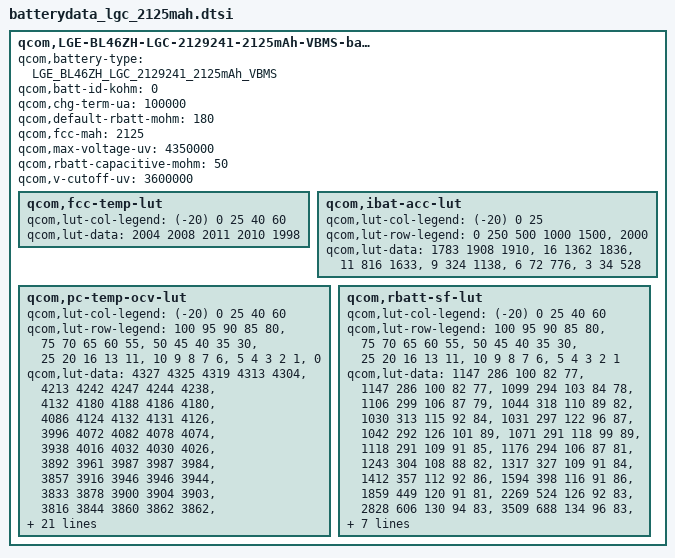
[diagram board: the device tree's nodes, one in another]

qcom,LGE-BL46ZH-LGC-2129241-2125mAh-VBMS-batterydata {
	qcom,battery-type = "LGE_BL46ZH_LGC_2129241_2125mAh_VBMS";
	qcom,batt-id-kohm = <0>;
	qcom,chg-term-ua = <100000>;
	qcom,default-rbatt-mohm = <180>;
	qcom,fcc-mah = <2125>;
	qcom,max-voltage-uv = <4350000>;
	qcom,rbatt-capacitive-mohm = <50>;
	qcom,v-cutoff-uv = <3600000>;

	qcom,fcc-temp-lut {
		qcom,lut-col-legend = <(-20) 0 25 40 60>;
		qcom,lut-data = <2004 2008 2011 2010 1998>;
	};

	qcom,ibat-acc-lut {
		qcom,lut-col-legend = <(-20) 0 25>;
		qcom,lut-row-legend = <0 250 500 1000 1500>,
					<2000>;
		qcom,lut-data = <1783 1908 1910>,
				<16 1362 1836>,
				<11 816 1633>,
				<9 324 1138>,
				<6 72 776>,
				<3 34 528>;
	};

	qcom,pc-temp-ocv-lut {
		qcom,lut-col-legend = <(-20) 0 25 40 60>;
		qcom,lut-row-legend = <100 95 90 85 80>,
					<75 70 65 60 55>,
					<50 45 40 35 30>,
					<25 20 16 13 11>,
					<10 9 8 7 6>,
					<5 4 3 2 1>,
					<0>;
		qcom,lut-data = <4327 4325 4319 4313 4304>,
				<4213 4242 4247 4244 4238>,
				<4132 4180 4188 4186 4180>,
				<4086 4124 4132 4131 4126>,
				<3996 4072 4082 4078 4074>,
				<3938 4016 4032 4030 4026>,
				<3892 3961 3987 3987 3984>,
				<3857 3916 3946 3946 3944>,
				<3833 3878 3900 3904 3903>,
				<3816 3844 3860 3862 3862>,
				<3800 3816 3831 3831 3830>,
				<3784 3794 3809 3809 3808>,
				<3766 3781 3790 3791 3790>,
				<3748 3768 3777 3776 3774>,
				<3726 3751 3766 3761 3756>,
				<3700 3728 3752 3744 3732>,
				<3670 3708 3728 3722 3710>,
				<3639 3697 3700 3694 3682>,
				<3612 3688 3683 3678 3666>,
				<3591 3679 3675 3670 3658>,
				<3580 3673 3672 3666 3656>,
				<3566 3664 3668 3664 3652>,
				<3552 3653 3664 3659 3648>,
				<3536 3640 3655 3650 3638>,
				<3516 3620 3636 3630 3616>,
				<3491 3595 3604 3596 3578>,
				<3459 3556 3554 3546 3530>,
				<3413 3502 3488 3484 3465>,
				<3343 3424 3406 3397 3379>,
				<3224 3294 3272 3262 3250>,
				<3000 3000 3000 3000 3000>;
	};

	qcom,rbatt-sf-lut {
		qcom,lut-col-legend = <(-20) 0 25 40 60>;
		qcom,lut-row-legend = <100 95 90 85 80>,
					<75 70 65 60 55>,
					<50 45 40 35 30>,
					<25 20 16 13 11>,
					<10 9 8 7 6>,
					<5 4 3 2 1>;
		qcom,lut-data = <1147 286 100 82 77>,
				<1147 286 100 82 77>,
				<1099 294 103 84 78>,
				<1106 299 106 87 79>,
				<1044 318 110 89 82>,
				<1030 313 115 92 84>,
				<1031 297 122 96 87>,
				<1042 292 126 101 89>,
				<1071 291 118 99 89>,
				<1118 291 109 91 85>,
				<1176 294 106 87 81>,
				<1243 304 108 88 82>,
				<1317 327 109 91 84>,
				<1412 357 112 92 86>,
				<1594 398 116 91 86>,
				<1859 449 120 91 81>,
				<2269 524 126 92 83>,
				<2828 606 130 94 83>,
				<3509 688 134 96 83>,
				<4108 749 139 97 84>,
				<4451 782 146 99 86>,
				<4947 816 153 103 87>,
				<5502 847 163 106 89>,
				<6096 877 171 108 89>,
				<6854 889 173 107 88>,
				<7856 919 175 106 87>,
				<9281 961 179 108 89>,
				<11598 1140 197 113 93>,
				<15459 1514 224 126 102>,
				<23606 2242 293 163 126>;
	};
};
